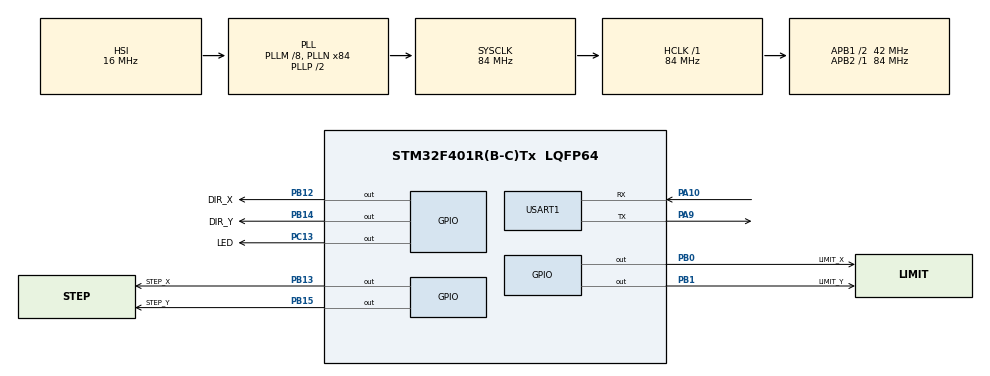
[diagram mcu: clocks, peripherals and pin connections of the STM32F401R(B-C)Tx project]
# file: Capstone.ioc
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FREERTOS.Tasks01=defaultTask,0,128,StartDefaultTask,Default,NULL,Dynamic,NULL,NULL
Mcu.Family=STM32F4
Mcu.Name=STM32F401R(B-C)Tx
Mcu.Package=LQFP64
NVIC.PriorityGroup=NVIC_PRIORITYGROUP_4
NVIC.TIM2_IRQn=true\:5\:0\:false\:false\:true\:true\:true\:true\:true
PA10.Mode=Asynchronous
PA10.Signal=USART1_RX
PA13.Mode=Serial_Wire
PA13.Signal=SYS_JTMS-SWDIO
PA14.Mode=Serial_Wire
PA14.Signal=SYS_JTCK-SWCLK
PA9.Mode=Asynchronous
PA9.Signal=USART1_TX
PB0.GPIO_Label=LIMIT_X
PB0.Signal=GPIO_Output
PB1.GPIO_Label=LIMIT_Y
PB1.Signal=GPIO_Output
PB12.GPIO_Label=DIR_X
PB12.Signal=GPIO_Output
PB13.GPIO_Label=STEP_X
PB13.Signal=GPIO_Output
PB14.GPIO_Label=DIR_Y
PB14.Signal=GPIO_Output
PB15.GPIO_Label=STEP_Y
PB15.Signal=GPIO_Output
PC13-ANTI_TAMP.GPIO_Label=LED
PC13-ANTI_TAMP.Signal=GPIO_Output
PH0\ -\ OSC_IN.Mode=HSE-External-Oscillator
PH0\ -\ OSC_IN.Signal=RCC_OSC_IN
PH1\ -\ OSC_OUT.Mode=HSE-External-Oscillator
PH1\ -\ OSC_OUT.Signal=RCC_OSC_OUT
ProjectManager.HeapSize=0x200
ProjectManager.StackSize=0x400
ProjectManager.TargetToolchain=STM32CubeIDE
RCC.48MHZClocksFreq_Value=42000000
RCC.AHBFreq_Value=84000000
RCC.APB1CLKDivider=RCC_HCLK_DIV2
RCC.APB1Freq_Value=42000000
RCC.APB1TimFreq_Value=84000000
RCC.APB2Freq_Value=84000000
RCC.APB2TimFreq_Value=84000000
RCC.CortexFreq_Value=84000000
RCC.HCLKFreq_Value=84000000
RCC.HSE_VALUE=25000000
RCC.HSI_VALUE=16000000
RCC.LSE_VALUE=32768
RCC.PLLM=8
RCC.PLLN=84
RCC.SYSCLKFreq_VALUE=84000000
RCC.SYSCLKSource=RCC_SYSCLKSOURCE_PLLCLK
RCC.VCOOutputFreq_Value=168000000
TIM2.AutoReloadPreload=TIM_AUTORELOAD_PRELOAD_ENABLE
TIM2.Period=100-1
TIM2.Prescaler=84-1
USART1.VirtualMode=VM_ASYNC
VP_FREERTOS_VS_CMSIS_V1.Mode=CMSIS_V1
VP_TIM2_VS_ClockSourceINT.Mode=Internal
board=custom

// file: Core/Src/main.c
/* USER CODE BEGIN Header */
/**
  ******************************************************************************
  * @file           : main.c
  * @brief          : Main program body
  ******************************************************************************
  * @attention
  *
  * Copyright (c) 2026 STMicroelectronics.
  * All rights reserved.
  *
  * This software is licensed under terms that can be found in the LICENSE file
  * in the root directory of this software component.
  * If no LICENSE file comes with this software, it is provided AS-IS.
  *
  ******************************************************************************
  */
/* USER CODE END Header */
#include "main.h"
#include "cmsis_os.h"
#include "tim.h"
#include "usart.h"
#include "gpio.h"

/* USER CODE BEGIN Includes */
#include "MachineApp.h"
/* USER CODE END Includes */

void SystemClock_Config(void);
void MX_FREERTOS_Init(void);

/* USER CODE BEGIN 0 */
volatile uint32_t counter = 0;
volatile uint32_t counter2 = 0;
/* USER CODE END 0 */

int main(void)
{

  /* MCU Configuration--------------------------------------------------------*/

  /* Reset of all peripherals, Initializes the Flash interface and the Systick. */
  HAL_Init();

  /* Configure the system clock */
  SystemClock_Config();

  /* Initialize all configured peripherals */
  MX_GPIO_Init();
  MX_TIM2_Init();
  MX_USART1_UART_Init();
  /* USER CODE BEGIN 2 */

  MachineApp_Init();

  /* USER CODE END 2 */

  /* Call init function for freertos objects (in cmsis_os2.c) */
  MX_FREERTOS_Init();

  /* Start scheduler */
  osKernelStart();

  /* We should never get here as control is now taken by the scheduler */

  /* Infinite loop */
  while (1)
  {

  }
}

void SystemClock_Config(void)
{
  RCC_OscInitTypeDef RCC_OscInitStruct = {0};
  RCC_ClkInitTypeDef RCC_ClkInitStruct = {0};

  /** Configure the main internal regulator output voltage
  */
  __HAL_RCC_PWR_CLK_ENABLE();
  __HAL_PWR_VOLTAGESCALING_CONFIG(PWR_REGULATOR_VOLTAGE_SCALE2);

  /** Initializes the RCC Oscillators according to the specified parameters
  * in the RCC_OscInitTypeDef structure.
  */
  RCC_OscInitStruct.OscillatorType = RCC_OSCILLATORTYPE_HSI;
  RCC_OscInitStruct.HSIState = RCC_HSI_ON;
  RCC_OscInitStruct.HSICalibrationValue = RCC_HSICALIBRATION_DEFAULT;
  RCC_OscInitStruct.PLL.PLLState = RCC_PLL_ON;
  RCC_OscInitStruct.PLL.PLLSource = RCC_PLLSOURCE_HSI;
  RCC_OscInitStruct.PLL.PLLM = 8;
  RCC_OscInitStruct.PLL.PLLN = 84;
  RCC_OscInitStruct.PLL.PLLP = RCC_PLLP_DIV2;
  RCC_OscInitStruct.PLL.PLLQ = 4;
  if (HAL_RCC_OscConfig(&RCC_OscInitStruct) != HAL_OK)
  {
    Error_Handler();
  }

  /** Initializes the CPU, AHB and APB buses clocks
  */
  RCC_ClkInitStruct.ClockType = RCC_CLOCKTYPE_HCLK|RCC_CLOCKTYPE_SYSCLK
                              |RCC_CLOCKTYPE_PCLK1|RCC_CLOCKTYPE_PCLK2;
  RCC_ClkInitStruct.SYSCLKSource = RCC_SYSCLKSOURCE_PLLCLK;
  RCC_ClkInitStruct.AHBCLKDivider = RCC_SYSCLK_DIV1;
  RCC_ClkInitStruct.APB1CLKDivider = RCC_HCLK_DIV2;
  RCC_ClkInitStruct.APB2CLKDivider = RCC_HCLK_DIV1;

  if (HAL_RCC_ClockConfig(&RCC_ClkInitStruct, FLASH_LATENCY_2) != HAL_OK)
  {
    Error_Handler();
  }
}

void Error_Handler(void)
{
  __disable_irq();
  while (1)
  {
  }
}

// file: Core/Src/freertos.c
/* USER CODE BEGIN Header */
/**
  ******************************************************************************
  * File Name          : freertos.c
  * Description        : Code for freertos applications
  ******************************************************************************
  * @attention
  *
  * Copyright (c) 2026 STMicroelectronics.
  * All rights reserved.
  *
  * This software is licensed under terms that can be found in the LICENSE file
  * in the root directory of this software component.
  * If no LICENSE file comes with this software, it is provided AS-IS.
  *
  ******************************************************************************
  */
/* USER CODE END Header */

#include "FreeRTOS.h"
#include "task.h"
#include "main.h"
#include "cmsis_os.h"

/* USER CODE BEGIN Includes */
#include "MachineApp.h"
/* USER CODE END Includes */

osThreadId defaultTaskHandle;

void StartDefaultTask(void const * argument);

void MX_FREERTOS_Init(void); /* (MISRA C 2004 rule 8.1) */

/* GetIdleTaskMemory prototype (linked to static allocation support) */
void vApplicationGetIdleTaskMemory( StaticTask_t **ppxIdleTaskTCBBuffer, StackType_t **ppxIdleTaskStackBuffer, uint32_t *pulIdleTaskStackSize );

/* USER CODE BEGIN GET_IDLE_TASK_MEMORY */
static StaticTask_t xIdleTaskTCBBuffer;
static StackType_t xIdleStack[configMINIMAL_STACK_SIZE];

void vApplicationGetIdleTaskMemory( StaticTask_t **ppxIdleTaskTCBBuffer, StackType_t **ppxIdleTaskStackBuffer, uint32_t *pulIdleTaskStackSize )
{
  *ppxIdleTaskTCBBuffer = &xIdleTaskTCBBuffer;
  *ppxIdleTaskStackBuffer = &xIdleStack[0];
  *pulIdleTaskStackSize = configMINIMAL_STACK_SIZE;
  /* place for user code */
}
/* USER CODE END GET_IDLE_TASK_MEMORY */

void MX_FREERTOS_Init(void) {

  /* Create the thread(s) */
  /* definition and creation of defaultTask */
  osThreadDef(defaultTask, StartDefaultTask, osPriorityNormal, 0, 128);
  defaultTaskHandle = osThreadCreate(osThread(defaultTask), NULL);

}

void StartDefaultTask(void const * argument)
{
  /* USER CODE BEGIN StartDefaultTask */
  /* Infinite loop */
  for(;;)
  {
	 MachineApp_Loop();
    osDelay(1);
  }
  /* USER CODE END StartDefaultTask */
}
